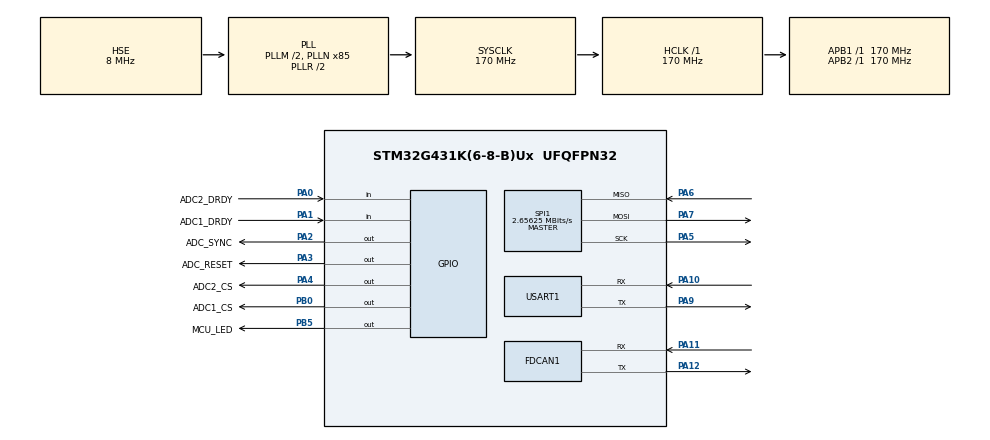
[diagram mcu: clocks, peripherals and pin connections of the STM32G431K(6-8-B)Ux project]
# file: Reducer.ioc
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FDCAN1.AutoRetransmission=ENABLE
FDCAN1.CalculateBaudRateData=2000000
FDCAN1.CalculateBaudRateNominal=500000
FDCAN1.CalculateTimeBitData=500
FDCAN1.CalculateTimeBitNominal=2000
FDCAN1.CalculateTimeQuantumData=29.41176470588235
FDCAN1.CalculateTimeQuantumNominal=117.64705882352942
FDCAN1.ClockDivider=FDCAN_CLOCK_DIV1
FDCAN1.DataPrescaler=5
FDCAN1.DataSyncJumpWidth=1
FDCAN1.DataTimeSeg1=14
FDCAN1.DataTimeSeg2=2
FDCAN1.FrameFormat=FDCAN_FRAME_FD_BRS
FDCAN1.NominalPrescaler=20
FDCAN1.NominalSyncJumpWidth=1
FDCAN1.NominalTimeSeg1=14
FDCAN1.NominalTimeSeg2=2
FDCAN1.StdFiltersNbr=1
Mcu.Family=STM32G4
Mcu.Name=STM32G431K(6-8-B)Ux
Mcu.Package=UFQFPN32
NVIC.FDCAN1_IT0_IRQn=true\:0\:0\:false\:false\:true\:true\:true\:true
NVIC.PriorityGroup=NVIC_PRIORITYGROUP_4
PA0.GPIO_Label=ADC2_DRDY
PA0.GPIO_PuPd=GPIO_PULLUP
PA0.Signal=GPIO_Input
PA1.GPIO_Label=ADC1_DRDY
PA1.GPIO_PuPd=GPIO_PULLUP
PA1.Signal=GPIO_Input
PA10.Mode=Asynchronous
PA10.Signal=USART1_RX
PA11.Mode=FDCAN_Activate
PA11.Signal=FDCAN1_RX
PA12.Mode=FDCAN_Activate
PA12.Signal=FDCAN1_TX
PA13.Mode=Serial_Wire
PA13.Signal=SYS_JTMS-SWDIO
PA14.Mode=Serial_Wire
PA14.Signal=SYS_JTCK-SWCLK
PA2.GPIO_Label=ADC_SYNC
PA2.GPIO_ModeDefaultOutputPP=GPIO_MODE_OUTPUT_PP
PA2.GPIO_PuPd=GPIO_NOPULL
PA2.GPIO_Speed=GPIO_SPEED_FREQ_VERY_HIGH
PA2.PinState=GPIO_PIN_SET
PA2.Signal=GPIO_Output
PA3.GPIO_Label=ADC_RESET
PA3.GPIO_ModeDefaultOutputPP=GPIO_MODE_OUTPUT_PP
PA3.GPIO_PuPd=GPIO_NOPULL
PA3.GPIO_Speed=GPIO_SPEED_FREQ_VERY_HIGH
PA3.PinState=GPIO_PIN_SET
PA3.Signal=GPIO_Output
PA4.GPIO_Label=ADC2_CS
PA4.GPIO_ModeDefaultOutputPP=GPIO_MODE_OUTPUT_PP
PA4.GPIO_PuPd=GPIO_NOPULL
PA4.GPIO_Speed=GPIO_SPEED_FREQ_VERY_HIGH
PA4.PinState=GPIO_PIN_SET
PA4.Signal=GPIO_Output
PA5.GPIO_Speed=GPIO_SPEED_FREQ_VERY_HIGH
PA5.Mode=Full_Duplex_Master
PA5.Signal=SPI1_SCK
PA6.GPIO_Speed=GPIO_SPEED_FREQ_VERY_HIGH
PA6.Mode=Full_Duplex_Master
PA6.Signal=SPI1_MISO
PA7.GPIO_Speed=GPIO_SPEED_FREQ_VERY_HIGH
PA7.Mode=Full_Duplex_Master
PA7.Signal=SPI1_MOSI
PA9.Mode=Asynchronous
PA9.Signal=USART1_TX
PB0.GPIO_Label=ADC1_CS
PB0.GPIO_ModeDefaultOutputPP=GPIO_MODE_OUTPUT_PP
PB0.GPIO_PuPd=GPIO_NOPULL
PB0.GPIO_Speed=GPIO_SPEED_FREQ_VERY_HIGH
PB0.PinState=GPIO_PIN_SET
PB0.Signal=GPIO_Output
PB5.GPIO_Label=MCU_LED
PB5.GPIO_ModeDefaultOutputPP=GPIO_MODE_OUTPUT_OD
PB5.GPIO_PuPd=GPIO_NOPULL
PB5.GPIO_Speed=GPIO_SPEED_FREQ_VERY_HIGH
PB5.Signal=GPIO_Output
PF0-OSC_IN.Mode=HSE-External-Oscillator
PF0-OSC_IN.Signal=RCC_OSC_IN
PF1-OSC_OUT.Mode=HSE-External-Oscillator
PF1-OSC_OUT.Signal=RCC_OSC_OUT
ProjectManager.HeapSize=0x200
ProjectManager.StackSize=0x1000
ProjectManager.TargetToolchain=CMake
RCC.ADC12Freq_Value=170000000
RCC.AHBFreq_Value=170000000
RCC.APB1Freq_Value=170000000
RCC.APB1TimFreq_Value=170000000
RCC.APB2Freq_Value=170000000
RCC.APB2TimFreq_Value=170000000
RCC.CortexFreq_Value=170000000
RCC.EXTERNAL_CLOCK_VALUE=12288000
RCC.HCLKFreq_Value=170000000
RCC.HSE_VALUE=8000000
RCC.HSI48_VALUE=48000000
RCC.HSI_VALUE=16000000
RCC.LSE_VALUE=32768
RCC.PLLM=RCC_PLLM_DIV2
RCC.PLLN=85
RCC.PLLSourceVirtual=RCC_PLLSOURCE_HSE
RCC.SYSCLKFreq_VALUE=170000000
RCC.SYSCLKSource=RCC_SYSCLKSOURCE_PLLCLK
RCC.USBFreq_Value=170000000
RCC.VCOOutputFreq_Value=340000000
SPI1.BaudRatePrescaler=SPI_BAUDRATEPRESCALER_64
SPI1.CLKPhase=SPI_PHASE_2EDGE
SPI1.CRCCalculation=SPI_CRCCALCULATION_DISABLE
SPI1.CalculateBaudRate=2.65625 MBits/s
SPI1.DataSize=SPI_DATASIZE_8BIT
SPI1.Direction=SPI_DIRECTION_2LINES
SPI1.Mode=SPI_MODE_MASTER
SPI1.NSSPMode=SPI_NSS_PULSE_DISABLE
SPI1.VirtualType=VM_MASTER
USART1.VirtualMode-Asynchronous=VM_ASYNC
VP_SYS_VS_DBSignals.Mode=DisableDeadBatterySignals
board=custom

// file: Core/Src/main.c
/* USER CODE BEGIN Header */
/**
  ******************************************************************************
  * @file           : main.c
  * @brief          : Main program body
  ******************************************************************************
  * @attention
  *
  * Copyright (c) 2026 STMicroelectronics.
  * All rights reserved.
  *
  * This software is licensed under terms that can be found in the LICENSE file
  * in the root directory of this software component.
  * If no LICENSE file comes with this software, it is provided AS-IS.
  *
  ******************************************************************************
  */
/* USER CODE END Header */
#include "main.h"
#include "fdcan.h"
#include "spi.h"
#include "usart.h"
#include "gpio.h"

/* USER CODE BEGIN Includes */
#include "user.h"
/* USER CODE END Includes */

void SystemClock_Config(void);

int main(void)
{

  /* MCU Configuration--------------------------------------------------------*/

  /* Reset of all peripherals, Initializes the Flash interface and the Systick. */
  HAL_Init();

  /* Configure the system clock */
  SystemClock_Config();

  /* Initialize all configured peripherals */
  MX_GPIO_Init();
  MX_FDCAN1_Init();
  MX_SPI1_Init();
  MX_USART1_UART_Init();
  /* USER CODE BEGIN 2 */
  setup();
  /* USER CODE END 2 */

  /* Infinite loop */
  /* USER CODE BEGIN WHILE */
  while (1)
  {
    loop();
    /* USER CODE END WHILE */

  }
}

void SystemClock_Config(void)
{
  RCC_OscInitTypeDef RCC_OscInitStruct = {0};
  RCC_ClkInitTypeDef RCC_ClkInitStruct = {0};

  /** Configure the main internal regulator output voltage
  */
  HAL_PWREx_ControlVoltageScaling(PWR_REGULATOR_VOLTAGE_SCALE1_BOOST);

  /** Initializes the RCC Oscillators according to the specified parameters
  * in the RCC_OscInitTypeDef structure.
  */
  RCC_OscInitStruct.OscillatorType = RCC_OSCILLATORTYPE_HSE;
  RCC_OscInitStruct.HSEState = RCC_HSE_ON;
  RCC_OscInitStruct.PLL.PLLState = RCC_PLL_ON;
  RCC_OscInitStruct.PLL.PLLSource = RCC_PLLSOURCE_HSE;
  RCC_OscInitStruct.PLL.PLLM = RCC_PLLM_DIV2;
  RCC_OscInitStruct.PLL.PLLN = 85;
  RCC_OscInitStruct.PLL.PLLP = RCC_PLLP_DIV2;
  RCC_OscInitStruct.PLL.PLLQ = RCC_PLLQ_DIV2;
  RCC_OscInitStruct.PLL.PLLR = RCC_PLLR_DIV2;
  if (HAL_RCC_OscConfig(&RCC_OscInitStruct) != HAL_OK)
  {
    Error_Handler();
  }

  /** Initializes the CPU, AHB and APB buses clocks
  */
  RCC_ClkInitStruct.ClockType = RCC_CLOCKTYPE_HCLK|RCC_CLOCKTYPE_SYSCLK
                              |RCC_CLOCKTYPE_PCLK1|RCC_CLOCKTYPE_PCLK2;
  RCC_ClkInitStruct.SYSCLKSource = RCC_SYSCLKSOURCE_PLLCLK;
  RCC_ClkInitStruct.AHBCLKDivider = RCC_SYSCLK_DIV1;
  RCC_ClkInitStruct.APB1CLKDivider = RCC_HCLK_DIV1;
  RCC_ClkInitStruct.APB2CLKDivider = RCC_HCLK_DIV1;

  if (HAL_RCC_ClockConfig(&RCC_ClkInitStruct, FLASH_LATENCY_4) != HAL_OK)
  {
    Error_Handler();
  }
}

void Error_Handler(void)
{
  /* USER CODE BEGIN Error_Handler_Debug */
  /* User can add his own implementation to report the HAL error return state */
  __disable_irq();
  while (1)
  {
    /* MCU_LED is active-low: use a visible explicit fault blink. */
    HAL_GPIO_WritePin(MCU_LED_GPIO_Port, MCU_LED_Pin, GPIO_PIN_RESET);
    for (volatile uint32_t delay = 0U; delay < 8000000U; delay++)
    {
      __NOP();
    }
    HAL_GPIO_WritePin(MCU_LED_GPIO_Port, MCU_LED_Pin, GPIO_PIN_SET);
    for (volatile uint32_t delay = 0U; delay < 8000000U; delay++)
    {
      __NOP();
    }
  }
  /* USER CODE END Error_Handler_Debug */
}
